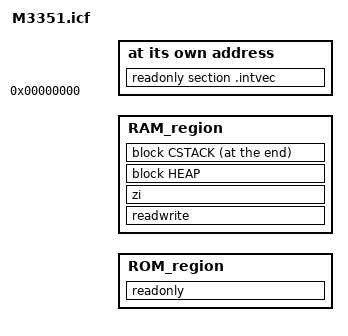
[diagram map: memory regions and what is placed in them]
/*###ICF### Section handled by ICF editor, don't touch! ****/
/*-Editor annotation file-*/
/* IcfEditorFile="$TOOLKIT_DIR$\config\ide\IcfEditor\cortex_v1_0.xml" */
/*-Specials-*/
define symbol __ICFEDIT_intvec_start__ = 0x00000000;

/* Default value for ENABLE_SRAM2, can be overridden by adding "ENABLE_SRAM2=1" in
 *   IAR Project -> Options -> Linker -> Config
 * To enable SRAM2:
 *   Must set CONFIG0[29] to 0 to disable SRAM ECC function to access SRAM2 as normal SRAM
 */
if (!isdefinedsymbol(ENABLE_SRAM2)) {
define symbol ENABLE_SRAM2 = 0;    /* Default: disable SRAM2 */
}

/* Validate ENABLE_SRAM2 value: must be 0 or 1 */
if ((ENABLE_SRAM2 != 0) && (ENABLE_SRAM2 != 1)) {
    error "ENABLE_SRAM2 must be 0 (disable) or 1 (enable)";
}

/*-Memory Regions-*/
define symbol __ICFEDIT_region_ROM_start__ = 0x00000000;
define symbol __ICFEDIT_region_ROM_end__   = ( 0x00100000 - 1 );

define symbol __ICFEDIT_region_RAM_start__ = 0x20000000;
define symbol __ICFEDIT_region_RAM_end__   = ( 0x20020000 + (ENABLE_SRAM2 * 0x8000) - 1 );

/*-Sizes-*/
if (!isdefinedsymbol(__ICFEDIT_size_cstack__)) {
define symbol __ICFEDIT_size_cstack__ = 0x00000400;
}
if (!isdefinedsymbol(__ICFEDIT_size_heap__)) {
define symbol __ICFEDIT_size_heap__   = 0x00000400;
}
/**** End of ICF editor section. ###ICF###*/

define memory mem with size = 4G;
define region ROM_region  = mem:[ from __ICFEDIT_region_ROM_start__ to __ICFEDIT_region_ROM_end__ ];
define region RAM_region  = mem:[ from __ICFEDIT_region_RAM_start__ to __ICFEDIT_region_RAM_end__ ];

define block CSTACK with alignment = 8, size = __ICFEDIT_size_cstack__ { };
define block HEAP   with alignment = 8, size = __ICFEDIT_size_heap__   { };

initialize by copy { readwrite };
do not initialize  { section .noinit };

place at address mem:__ICFEDIT_intvec_start__ { readonly section .intvec };

place in ROM_region  { readonly };
place in RAM_region  { readwrite, zi, block HEAP };
place at end of RAM_region { block CSTACK };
